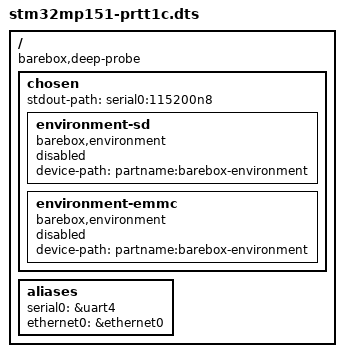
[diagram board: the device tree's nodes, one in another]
// SPDX-License-Identifier: (GPL-2.0-or-later OR BSD-3-Clause)
// SPDX-FileCopyrightText: 2021 David Jander, Protonic Holland
// SPDX-FileCopyrightText: 2021 Oleksij Rempel, Pengutronix
/dts-v1/;

#include <arm/st/stm32mp151a-prtt1c.dts>

#include "stm32mp151.dtsi"

/ {
	barebox,deep-probe;

	chosen {
		stdout-path = "serial0:115200n8";

		environment-sd {
			compatible = "barebox,environment";
			device-path = &sdmmc1, "partname:barebox-environment";
			status = "disabled";
		};

		environment-emmc {
			compatible = "barebox,environment";
			device-path = &sdmmc2, "partname:barebox-environment";
			status = "disabled";
		};
	};

	aliases {
		serial0 = &uart4;
		ethernet0 = &ethernet0;
	};
};
